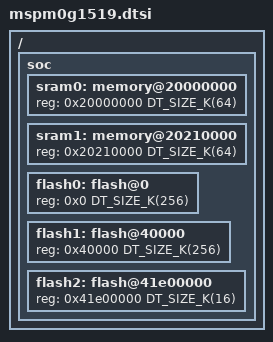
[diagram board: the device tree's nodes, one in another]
/* SPDX-License-Identifier: Apache-2.0 */

#include <mem.h>
#include <ti/mspm0/g/mspm0gx51x.dtsi>

/ {
	soc {
		/*
		 * Sram Bank 0 (sram0) has ECC checking
		 * Sram Bank 1 (sram1) is unchecked
		 */
		sram0: memory@20000000 {
			reg = <0x20000000 DT_SIZE_K(64)>;
		};

		sram1: memory@20210000 {
			reg = <0x20210000 DT_SIZE_K(64)>;
		};

		flash0: flash@0 {
			reg = <0x0 DT_SIZE_K(256)>;
			ranges = <0x0 0x0 DT_SIZE_K(256)>;
			#address-cells = <1>;
			#size-cells = <1>;
		};

		flash1: flash@40000 {
			reg = <0x40000 DT_SIZE_K(256)>;
			ranges = <0x0 0x40000 DT_SIZE_K(256)>;
			#address-cells = <1>;
			#size-cells = <1>;
		};

		flash2: flash@41e00000 {
			reg = <0x41e00000 DT_SIZE_K(16)>;
			ranges = <0x0 0x41e00000 DT_SIZE_K(16)>;
			#address-cells = <1>;
			#size-cells = <1>;
		};
	};
};
